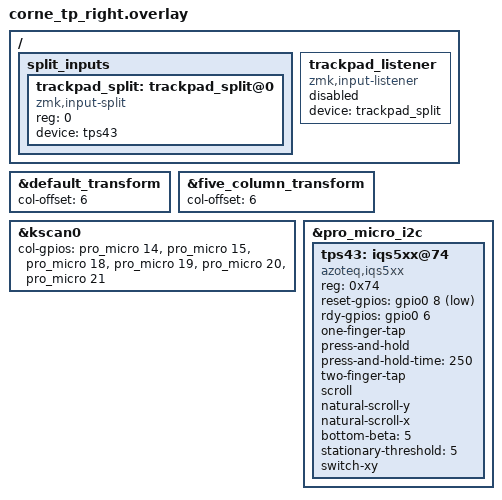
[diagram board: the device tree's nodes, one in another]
/*
 * Copyright (c) 2020 Pete Johanson
 *
 * SPDX-License-Identifier: MIT
 */

#include "corne.dtsi"

&default_transform {
    col-offset = <6>;
};

&five_column_transform {
    col-offset = <6>;
};

&kscan0 {
    col-gpios
        = <&pro_micro 14 GPIO_ACTIVE_HIGH>
        , <&pro_micro 15 GPIO_ACTIVE_HIGH>
        , <&pro_micro 18 GPIO_ACTIVE_HIGH>
        , <&pro_micro 19 GPIO_ACTIVE_HIGH>
        , <&pro_micro 20 GPIO_ACTIVE_HIGH>
        , <&pro_micro 21 GPIO_ACTIVE_HIGH>
        ;
};

/ {
    split_inputs {
    #address-cells = <1>;
    #size-cells = <0>;

    trackpad_split: trackpad_split@0 {
      compatible = "zmk,input-split";
      reg = <0>;
      device = <&tps43>;
    };
  };

    trackpad_listener: trackpad_listener {
      compatible = "zmk,input-listener";
      status = "disabled";
      device = <&trackpad_split>;
    };
};


&pro_micro_i2c {
  status = "okay";
  tps43: iqs5xx@74 {
    status = "okay";
    compatible = "azoteq,iqs5xx";
    reg = <0x74>;

    reset-gpios = <&gpio0 8 GPIO_ACTIVE_LOW>;
    rdy-gpios = <&gpio0 6 GPIO_ACTIVE_HIGH>;

    /*
      * Potentially non-exhaustive list of configuration options.
      * See: dts/bindings/input/azoteq,iqs5xx-common.yaml for a full list.
      */
    one-finger-tap;
    press-and-hold;
    press-and-hold-time = <250>;
    two-finger-tap;

    scroll;
    natural-scroll-y;
    natural-scroll-x;

    bottom-beta = <5>;
    stationary-threshold = <5>;

    switch-xy;
  };
};
